# MEC1723N_B0_LJ register map
Vendor: Microchip Technology; Series: MEC172x; File version: 0
CPU: CM4 r1p0, little endian, MPU, FPU, 3 interrupt priority bits, 172 interrupts
Registers are 32-bit, read-write, reset 0x0 unless marked. A register's access mark holds for its fields unless they carry their own. Offsets are from the block's base; [hi:lo] are bit positions; {n}, {i} and the like mark numbered series.

## PCR — The Power, Clocks, and Resets (PCR) Section identifies clock sources, and reset inputs to the chip.
Base 0x40080100
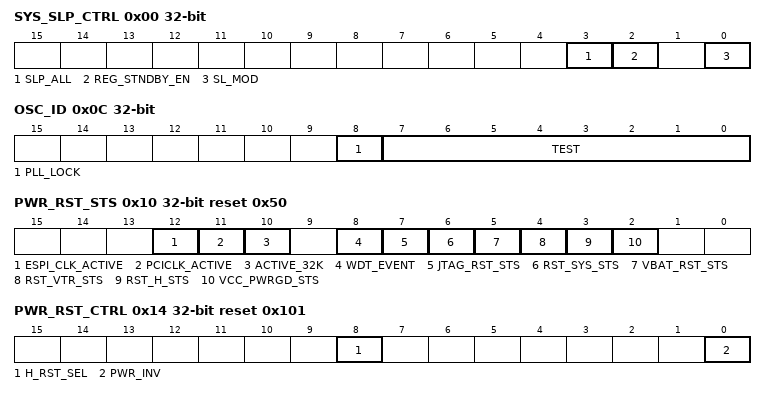
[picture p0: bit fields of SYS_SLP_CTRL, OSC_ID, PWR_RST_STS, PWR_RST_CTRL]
0x00 SYS_SLP_CTRL — System Sleep Control
  [3] SLP_ALL — Initiates the System Sleep mode
  [2] REG_STNDBY_EN — Regulator Standby Enable
  [0] SL_MOD — Selects the System Sleep mode
0x04 PROC_CLK_CTRL reset 0x4 — Processor Clock Control Register [7:0] Processor Clock Divide Value (PROC_DIV)
  [7:0] DIV — Selects the EC clock rate
    1=DIVIDE_BY_1 (1: divide 48 MHz Ring Oscillator by 1); 3=DIVIDE_BY_3 (3: divide 48 MHz Ring Oscillator by 3); 4=DIVIDE_BY_4 (4: divide 48 MHz Ring Oscillator by 4); 16=DIVIDE_BY_16 (16: divide 48 MHz Ring Oscillator by 16); 48=DIVIDE_BY_48 (48: divide 48 MHz Ring Oscillator by 48)
0x08 SLOW_CLK_CTRL reset 0x1E0 — Configures the EC_CLK clock domain
  [9:0] DIV — SLOW_CLOCK_DIVIDE. n=Divide by n; 0=Clock off
0x0C OSC_ID — Oscillator ID Register
  [8] PLL_LOCK — PLL Lock Status
  [7:0] TEST — Test bits
0x10 PWR_RST_STS reset 0x50 — PCR Power Reset Status Register
  [12] ESPI_CLK_ACTIVE
  [11] PCICLK_ACTIVE — PCICLK_ACTIVE (PCICLK_ACTIVE)
  [10] ACTIVE_32K — 32K ACTIVE (ACTIVE_32K)
  [8] WDT_EVENT — Indicates that a WDT_EVENT happened. (R/W1C) 0 = Not active. 1 = A WDT_EVENT occured.
  [7] JTAG_RST_STS — Indicates status of JTAG_TRST# pin. 0 = No JTAG reset occurred since the last time this bit was cleared. 1 = A reset occurred because of a JTAG command.
  [6] RST_SYS_STS — Indicates the status of RESET_SYS.(R/W1C) 0 = No reset occurred since the last time this bit was cleared. 1 = A reset occurred.
  [5] VBAT_RST_STS — VBAT reset status 0 = No reset occurred while VTR was off or since the last time this bit was cleared. 1 = A reset occurred.(R/WC)
  [4] RST_VTR_STS — Indicates the status of RESET_VTR. 0 = reset active. 1 = reset not active.(R/W1C)
  [3] RST_H_STS — Indicates the status of RESET_VCC. 0 = reset active. 1 = reset not active.
  [2] VCC_PWRGD_STS — Indicates the status of VCC_PWRGD. 0 = PWRGD not asserted. 1 = PWRGD asserte.
0x14 PWR_RST_CTRL reset 0x101 — Power Reset Control Register
  [8] H_RST_SEL — Determines what generates the internal platform reset signal. 1=LRESET# pin; 0=eSPI PLTRST# VWire
  [0] PWR_INV — Used by FW to control internal RESET_VCC signal function and external PWROK pin. This bit is read-only when VCC_PWRGD is de-asserted low.
0x18 SYS_RST — System Reset Register
  [8] SOFT_SYS_RST — A write of a 1 forces an assertion of the RESET_SYS reset signal, resetting the device. A write of 0 has no effect.
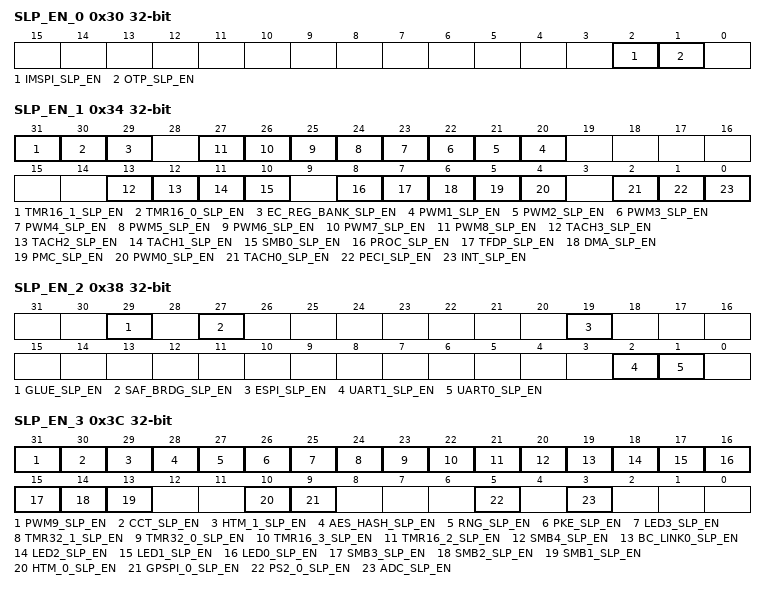
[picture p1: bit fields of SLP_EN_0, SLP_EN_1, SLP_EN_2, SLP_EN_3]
0x30 SLP_EN_0 — Sleep Enable 0 Register
  [2] IMSPI_SLP_EN — IMSPI Sleep Enable
  [1] OTP_SLP_EN — OTP Enable
0x34 SLP_EN_1 — Sleep Enable 1 Register
  [31] TMR16_1_SLP_EN — TIMER16_1 Sleep Enable (TIMER16_1_SLP_EN)
  [30] TMR16_0_SLP_EN — TIMER16_0 Sleep Enable (TIMER16_0_SLP_EN)
  [29] EC_REG_BANK_SLP_EN — EC_REG_BANK Sleep Enable (EC_REG_BANK_SLP_EN)
  [n+19] PWM{n}_SLP_EN (n=1..8) — PWM{n} Sleep Enable (PWM{n}_SLP_EN)
  [13] TACH3_SLP_EN — TACH3 Sleep Enable (TACH3_SLP_EN)
  [12] TACH2_SLP_EN — TACH2 Sleep Enable (TACH2_SLP_EN)
  [11] TACH1_SLP_EN — TACH1 Sleep Enable (TACH1_SLP_EN)
  [10] SMB0_SLP_EN — SMB0 Sleep Enable (SMB0_SLP_EN)
  [8] PROC_SLP_EN — PROCESSOR Sleep Enable (PROCESSOR_SLP_EN)
  [7] TFDP_SLP_EN — TFDP Sleep Enable (TFDP_SLP_EN)
  [6] DMA_SLP_EN — DMA Sleep Enable (DMA_SLP_EN)
  [5] PMC_SLP_EN — PMC Sleep Enable (PMC_SLP_EN)
  [4] PWM0_SLP_EN — PWM0 Sleep Enable (PWM0_SLP_EN)
  [2] TACH0_SLP_EN — TACH0 Sleep Enable (TACH0_SLP_EN)
  [1] PECI_SLP_EN — PECI Sleep Enable
  [0] INT_SLP_EN — Interrupt Sleep Enable
0x38 SLP_EN_2 — Sleep Enable 2 Register
  [29] GLUE_SLP_EN — GLUE Sleep Enable
  [27] SAF_BRDG_SLP_EN — SAF BRIDGE Sleep Enable
  [19] ESPI_SLP_EN — eSPI Sleep Enable
  [2] UART1_SLP_EN — UART 1 Sleep Enable
  [1] UART0_SLP_EN — UART 0 Sleep Enable
0x3C SLP_EN_3 — Sleep Enable 3 Register
  [31] PWM9_SLP_EN — PWM9 Sleep Enable (PWM9_SLP_EN)
  [30] CCT_SLP_EN — Capture Compare Timer Sleep Enable (CCTIMER_SLP_EN)
  [29] HTM_1_SLP_EN — Hibernation TIMER 1 Sleep Enable (HTM_1_SLP_EN)
  [28] AES_HASH_SLP_EN — AES_HASH Sleep Enable
  [27] RNG_SLP_EN — RNG Sleep Enable
  [26] PKE_SLP_EN — PKE Sleep Enable
  [25] LED3_SLP_EN — LED3 Sleep Enable (LED3_SLP_EN)
  [24] TMR32_1_SLP_EN — TIMER32_1 Sleep Enable (TIMER32_1_SLP_EN)
  [23] TMR32_0_SLP_EN — TIMER32_0 Sleep Enable (TIMER32_0_SLP_EN)
  [22] TMR16_3_SLP_EN — TIMER16_3 Sleep Enable (TIMER16_3_SLP_EN)
  [21] TMR16_2_SLP_EN — TIMER16_2 Sleep Enable (TIMER16_2_SLP_EN)
  [20] SMB4_SLP_EN — SMB4 Sleep Enable (SMB4_SLP_EN)
  [19] BC_LINK0_SLP_EN — BC_LINK0 Sleep Enable (BC_LINK0_SLP_EN)
  [18] LED2_SLP_EN — LED2 Sleep Enable (LED2_SLP_EN)
  [17] LED1_SLP_EN — LED1 Sleep Enable (LED1_SLP_EN)
  [16] LED0_SLP_EN — LED0 Sleep Enable (LED0_SLP_EN)
  [15] SMB3_SLP_EN — SMB3 Sleep Enable (SMB3_SLP_EN)
  [14] SMB2_SLP_EN — SMB2 Sleep Enable (SMB2_SLP_EN)
  [13] SMB1_SLP_EN — SMB1 Sleep Enable (SMB1_SLP_EN)
  [10] HTM_0_SLP_EN — Hibernation Timer 0 Sleep Enable (HTM_0_SLP_EN)
  [9] GPSPI_0_SLP_EN — GPSPI 0 Sleep Enable (GPSPI_0_SLP_EN)
  [5] PS2_0_SLP_EN — PS2_0 Sleep Enable (PS2_0_SLP_EN)
  [3] ADC_SLP_EN — ADC Sleep Enable (ADC_SLP_EN)
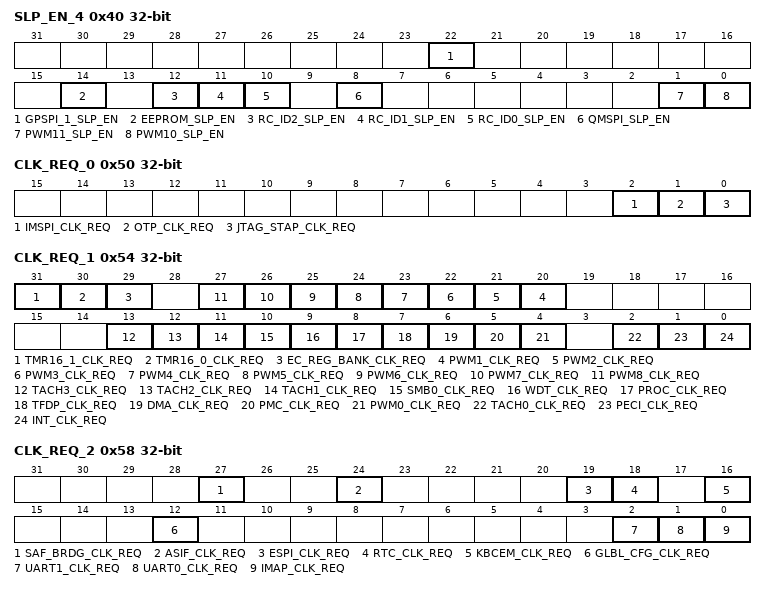
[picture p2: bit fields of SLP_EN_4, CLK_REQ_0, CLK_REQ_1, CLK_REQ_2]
0x40 SLP_EN_4 — Sleep Enable 4 Register
  [22] GPSPI_1_SLP_EN — GPSPI 1 Sleep Enable (GPSPI_1_SLP_EN)
  [14] EEPROM_SLP_EN — EEPROM Sleep Enable (EEPROM_SLP_EN)
  [12] RC_ID2_SLP_EN — RC_ID2 Sleep Enable (RC_ID2_SLP_EN)
  [11] RC_ID1_SLP_EN — RC_ID1 Sleep Enable (RC_ID1_SLP_EN)
  [10] RC_ID0_SLP_EN — RC_ID0 Sleep Enable (RC_ID0_SLP_EN)
  [8] QMSPI_SLP_EN — Quad Master SPI Sleep Enable
  [1] PWM11_SLP_EN — PWM11 Sleep Enable (PWM11_SLP_EN)
  [0] PWM10_SLP_EN — PWM10 Sleep Enable (PWM10_SLP_EN)
0x50 CLK_REQ_0 — Clock Required 0 Register
  [2] IMSPI_CLK_REQ — IMSPI Sleep clock Required
  [1] OTP_CLK_REQ — OTP Enable
  [0] JTAG_STAP_CLK_REQ — JTAG STAP Enable
0x54 CLK_REQ_1 — Clock Required 1 Register
  [31] TMR16_1_CLK_REQ — TIMER16_1 Clock Required (TIMER16_1_CLK_REQ)
  [30] TMR16_0_CLK_REQ — TIMER16_0 Clock Required (TIMER16_0_CLK_REQ)
  [29] EC_REG_BANK_CLK_REQ — EC_REG_BANK Clock Required (EC_REG_BANK_CLK_REQ)
  [n+19] PWM{n}_CLK_REQ (n=1..8) — PWM{n} Clock Required (PWM{n}_CLK_REQ)
  [13] TACH3_CLK_REQ — TACH3 Clock Required (TACH3_CLK_REQ)
  [12] TACH2_CLK_REQ — TACH2 Clock Required (TACH2_CLK_REQ)
  [11] TACH1_CLK_REQ — TACH1 Clock Required (TACH1_CLK_REQ)
  [10] SMB0_CLK_REQ — SMB0 Clock Required (SMB0_CLK_REQ)
  [9] WDT_CLK_REQ — WDT Clock Required (WDT_CLK_REQ)
  [8] PROC_CLK_REQ — PROCESSOR Clock Required (PROCESSOR_CLK_REQ)
  [7] TFDP_CLK_REQ — TFDP Clock Required (TFDP_CLK_REQ)
  [6] DMA_CLK_REQ — DMA Clock Required (DMA_CLK_REQ)
  [5] PMC_CLK_REQ — PMC Clock Required (PMC_CLK_REQ)
  [4] PWM0_CLK_REQ — PWM0 Clock Required (PWM0_CLK_REQ)
  [2] TACH0_CLK_REQ — TACH0 Clock Required (TACH0_CLK_REQ)
  [1] PECI_CLK_REQ — PECI Clock Required
  [0] INT_CLK_REQ — Interrupt Clock Required
0x58 CLK_REQ_2 — Clock Required 2 Register
  [27] SAF_BRDG_CLK_REQ — SAF BRIDGE Clock Required
  [24] ASIF_CLK_REQ — ASIF Clock Required
  [19] ESPI_CLK_REQ — eSPI Clock Required
  [18] RTC_CLK_REQ — RTC Clock Required (RTC_CLK_REQ)
  [16] KBCEM_CLK_REQ — 8042EM Clock Required (8042EM_CLK_REQ)
  [12] GLBL_CFG_CLK_REQ — GLBL_CFG (GLBL_CFG_CLK_REQ)
  [2] UART1_CLK_REQ — UART 1 Clock Required
  [1] UART0_CLK_REQ — UART 0 Clock Required
  [0] IMAP_CLK_REQ — IMAP Clock Required (IMAP_CLK_REQ)
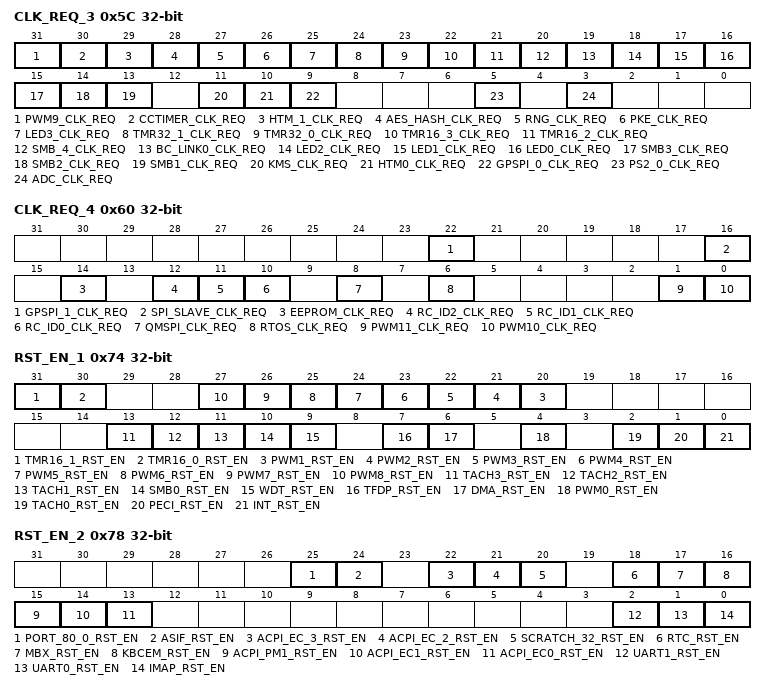
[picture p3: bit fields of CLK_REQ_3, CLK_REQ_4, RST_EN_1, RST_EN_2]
0x5C CLK_REQ_3 — Clock Required 3 Register
  [31] PWM9_CLK_REQ — PWM9 Clock Required (PWM9_CLK_REQ)
  [30] CCTIMER_CLK_REQ — Capture Compare Timer Clock Required (CCTIMER_CLK_REQ)
  [29] HTM_1_CLK_REQ — Hibernation TIMER 1 Clock Required (HTM_1_CLK_REQ)
  [28] AES_HASH_CLK_REQ — AES_HASH Clock Required
  [27] RNG_CLK_REQ — RNG Clock Required
  [26] PKE_CLK_REQ — PKE Clock Required
  [25] LED3_CLK_REQ — LED3 Clock Required (LED3_CLK_REQ)
  [24] TMR32_1_CLK_REQ — TIMER32_1 Clock Required (TIMER32_1_CLK_REQ)
  [23] TMR32_0_CLK_REQ — TIMER32_0 Clock Required (TIMER32_0_CLK_REQ)
  [22] TMR16_3_CLK_REQ — TIMER16_3 Clock Required (TIMER16_3_CLK_REQ)
  [21] TMR16_2_CLK_REQ — TIMER16_2 Clock Required (TIMER16_2_CLK_REQ)
  [20] SMB_4_CLK_REQ — SMB 4 Clock Required (SMB_4_CLK_REQ)
  [19] BC_LINK0_CLK_REQ — BC_LINK0 Clock Required (BC_LINK0_CLK_REQ)
  [18] LED2_CLK_REQ — LED2 Clock Required (LED2_CLK_REQ)
  [17] LED1_CLK_REQ — LED1 Clock Required (LED1_CLK_REQ)
  [16] LED0_CLK_REQ — LED0 Clock Required (LED0_CLK_REQ)
  [15] SMB3_CLK_REQ — SMB3 Clock Required (SMB3_CLK_REQ)
  [14] SMB2_CLK_REQ — SMB2 Clock Required (SMB2_CLK_REQ)
  [13] SMB1_CLK_REQ — SMB1 Clock Required (SMB1_CLK_REQ)
  [11] KMS_CLK_REQ — KEYSCAN Clock Required (KMS_CLK_REQ)
  [10] HTM0_CLK_REQ — Hibernation TIMER 0 Clock Required (HTM_0_CLK_REQ)
  [9] GPSPI_0_CLK_REQ — GPSPI 0 Clock Required (GPSPI_0_CLK_REQ)
  [5] PS2_0_CLK_REQ — PS2_0 Clock Required (PS2_0_CLK_REQ)
  [3] ADC_CLK_REQ — ADC Clock Required (ADC_CLK_REQ)
0x60 CLK_REQ_4 — Clock Required 4 Register
  [22] GPSPI_1_CLK_REQ — GPSPI 1 Clock Required (GPSPI_1_CLK_REQ)
  [16] SPI_SLAVE_CLK_REQ — SPI SLAVE Clock Required (SPI_SLAVE_CLK_REQ)
  [14] EEPROM_CLK_REQ — EEPROM Clock Required (EEPROM_CLK_REQ)
  [12] RC_ID2_CLK_REQ — RC_ID2 Clock Required (RC_ID2_CLK_REQ)
  [11] RC_ID1_CLK_REQ — RC_ID1 Clock Required (RC_ID1_CLK_REQ)
  [10] RC_ID0_CLK_REQ — RC_ID0 Clock Required (RC_ID0_CLK_REQ)
  [8] QMSPI_CLK_REQ — Quad Master SPI Clock Required
  [6] RTOS_CLK_REQ — RTOS Clock Required (RTOS_CLK_REQ)
  [1] PWM11_CLK_REQ — PWM11 Clock Required (PWM11_CLK_REQ)
  [0] PWM10_CLK_REQ — PWM10 Clock Required (PWM10_CLK_REQ)
0x70 RST_EN_0 — Reset Enable 0 Register
  [1] OTP_RST_EN — OTP Reset Enable
0x74 RST_EN_1 — Reset Enable 1 Register
  [31] TMR16_1_RST_EN — TIMER16_1 Reset Enable (TIMER16_1_RST_EN)
  [30] TMR16_0_RST_EN — TIMER16_0 Reset Enable (TIMER16_0_RST_EN)
  [n+19] PWM{n}_RST_EN (n=1..8) — PWM{n} Reset Enable (PWM{n}_RST_EN)
  [13] TACH3_RST_EN — TACH3 Reset Enable (TACH3_RST_EN)
  [12] TACH2_RST_EN — TACH2 Reset Enable (TACH2_RST_EN)
  [11] TACH1_RST_EN — TACH1 Reset Enable (TACH1_RST_EN)
  [10] SMB0_RST_EN — SMB0 Reset Enable (SMB0_RST_EN)
  [9] WDT_RST_EN — WDT Reset Enable (WDT_RST_EN)
  [7] TFDP_RST_EN — TFDP Reset Enable (TFDP_RST_EN)
  [6] DMA_RST_EN — DMA Reset Enable (DMA_RST_EN)
  [4] PWM0_RST_EN — PWM0 Reset Enable (PWM0_RST_EN)
  [2] TACH0_RST_EN — TACH0 Reset Enable (TACH0_RST_EN)
  [1] PECI_RST_EN — PECI Reset Enable
  [0] INT_RST_EN — Interrupt Reset Enable
0x78 RST_EN_2 — Reset Enable 2 Register
  [25] PORT_80_0_RST_EN — Port 80 0 Reset Enable
  [24] ASIF_RST_EN — ASIF Reset Enable
  [22] ACPI_EC_3_RST_EN — ACPI EC 3 Reset Enable (ACPI_EC_3_RST_EN)
  [21] ACPI_EC_2_RST_EN — ACPI EC 2 Reset Enable (ACPI_EC_2_RST_EN)
  [20] SCRATCH_32_RST_EN — SCRATCH 32 Reset Enable
  [18] RTC_RST_EN — RTC Reset Enable (RTC_RST_EN)
  [17] MBX_RST_EN — Mailbox Reset Enable (MBX_RST_EN)
  [16] KBCEM_RST_EN — 8042EM Reset Enable (8042EM_RST_EN)
  [15] ACPI_PM1_RST_EN — ACPI PM1 Reset Enable (ACPI_PM1_RST_EN)
  [14] ACPI_EC1_RST_EN — ACPI EC 1 Reset Enable (ACPI_EC_1_RST_EN)
  [13] ACPI_EC0_RST_EN — ACPI EC 0 Reset Enable (ACPI_EC_0_RST_EN)
  [2] UART1_RST_EN — UART 1 Reset Enable
  [1] UART0_RST_EN — UART 0 Reset Enable
  [0] IMAP_RST_EN — IMAP Reset Enable (IMAP_RST_EN)
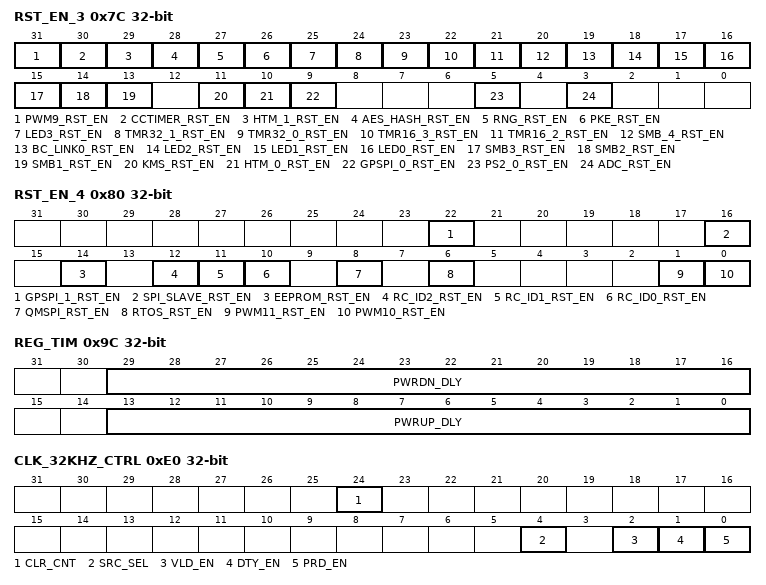
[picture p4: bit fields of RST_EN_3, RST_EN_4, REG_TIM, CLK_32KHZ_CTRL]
0x7C RST_EN_3 — Reset Enable 3 Register
  [31] PWM9_RST_EN — PWM9 Reset Enable (PWM9_RST_EN)
  [30] CCTIMER_RST_EN — Capture Compare Timer Reset Enable (CCTIMER_RST_EN)
  [29] HTM_1_RST_EN — Hibernation TIMER 1 Reset Enable (HTM_1_RST_EN)
  [28] AES_HASH_RST_EN — AES_HASH Reset Enable
  [27] RNG_RST_EN — RNG Reset Enable
  [26] PKE_RST_EN — PKE Reset Enable
  [25] LED3_RST_EN — LED3 Reset Enable (LED3_RST_EN)
  [24] TMR32_1_RST_EN — TIMER32_1 Reset Enable (TIMER32_1_RST_EN)
  [23] TMR32_0_RST_EN — TIMER32_0 Reset Enable (TIMER32_0_RST_EN)
  [22] TMR16_3_RST_EN — TIMER16_3 Reset Enable (TIMER16_3_RST_EN)
  [21] TMR16_2_RST_EN — TIMER16_2 Reset Enable (TIMER16_2_RST_EN)
  [20] SMB_4_RST_EN — SMB 4 Reset Enable (SMB_4_RST_EN)
  [19] BC_LINK0_RST_EN — BC_LINK0 Reset Enable (BC_LINK0_RST_EN)
  [18] LED2_RST_EN — LED2 Reset Enable (LED2_RST_EN)
  [17] LED1_RST_EN — LED1 Reset Enable (LED1_RST_EN)
  [16] LED0_RST_EN — LED0 Reset Enable (LED0_RST_EN)
  [15] SMB3_RST_EN — SMB3 Reset Enable (SMB3_RST_EN)
  [14] SMB2_RST_EN — SMB2 Reset Enable (SMB2_RST_EN)
  [13] SMB1_RST_EN — SMB1 Reset Enable (SMB1_RST_EN)
  [11] KMS_RST_EN — KEYSCAN Reset Enable (KMS_RST_EN)
  [10] HTM_0_RST_EN — Hibernation TIMER 0 Reset Enable (HTM_0_RST_EN)
  [9] GPSPI_0_RST_EN — GPSPI 0 Reset Enable (GPSPI_0_RST_EN)
  [5] PS2_0_RST_EN — PS2_0 Reset Enable (PS2_0_RST_EN)
  [3] ADC_RST_EN — ADC Reset Enable (ADC_RST_EN)
0x80 RST_EN_4 — Reset Enable 4 Register
  [22] GPSPI_1_RST_EN — GPSPI 1 Reset Enable (GPSPI_1_RST_EN)
  [16] SPI_SLAVE_RST_EN — SPI SLAVE Reset Enable (SPI_SLAVE_RST_EN)
  [14] EEPROM_RST_EN — EEPROM Reset Enable (EEPROM_RST_EN)
  [12] RC_ID2_RST_EN — RC_ID2 Reset Enable (RC_ID2_RST_EN)
  [11] RC_ID1_RST_EN — RC_ID1 Reset Enable (RC_ID1_RST_EN)
  [10] RC_ID0_RST_EN — RC_ID0 Reset Enable (RC_ID0_RST_EN)
  [8] QMSPI_RST_EN — Quad Master SPI Reset Enable
  [6] RTOS_RST_EN — RTOS Reset Enable (RTOS_RST_EN)
  [1] PWM11_RST_EN — PWM11 Reset Enable (PWM11_RST_EN)
  [0] PWM10_RST_EN — PWM10 Reset Enable (PWM10_RST_EN)
0x84 LOCK_REG reset 0xA6382D4D — LOCK Register
  [31:0] PCR_RST_EN_LOCK — PCR Reset Enable Lock Register.
0x88 SFT_VBAT_POR — SOFT VBAT Register
  [0] SFT_VBAT_POR — SOFT VBAT POWER ON RESET.
0x8C PLL_REF reset 0x3 — PLL reference clock select.
  [1:0] PLL_REF — Source 32kHz MUX Select for the PLL reference clock source. 0 = Internal Silicon Oscillator 1 = XTAL 2 = VTR PIN 32KHZ_IN 3 = NONE-OFF
0x94 REG_CTRL_RUN ro — Regulator Control Running Register
  [31:0] CTRL_RUN — Regulator Control Running Register.
0x98 REG_CTRL_SLP ro — Regulator Control Sleeping Register
  [31:0] CTRL_SLP — Regulator Control Running Register.
0x9C REG_TIM ro — Regulator Time Register
  [29:16] PWRDN_DLY — Regulator Power Down delay Register.
  [13:0] PWRUP_DLY — Regulator Power Up delay Register.
0xA4 BNDGP_CTRL_RUN ro — Bandgap Control Running Register
  [31:0] CTRL_RUN — Regulator Control Running Register.
0xA8 BNDGP_CTRL_SLP ro — Bandgap Control Sleeping Register
  [31:0] CTRL_SLP — Regulator Control Running Register.
0xC0 CLK_PRD ro — 32KHz Period Counter Register
  [31:0] CLK_PRD — Counter 32khz period Counts system clock cycles between 2 positive edges of an 32kHz clock.
0xC4 CLK_HGHPLS ro — 32KHz Clock High Pulse Register
  [31:0] CLK_HGHPLS — Counter 32khz High Counts how many system clock cycles the 32kHz clock remains HIGH for.
0xC8 CLK_MINPRD ro — 32KHz Clock Min Period Register
  [31:0] CLK_MINPRD — This is the minimum period count that is acceptable for the 32kHz counter to flag a PASS status.
0xCC CLK_MAXPRD — 32KHz Clock Max Period Register
  [31:0] CLK_MAXPRD — This is the maximum period count that is acceptable for the 32kHz counter to flag a PASS status.
0xD0 CLK_DTYVRTN ro — 32KHz Clock Duty Variation Register
  [31:0] CLK_DTYVRTN — This is the difference in system clocks between the 32kHz clocks High Pulse Width and its Low Pulse Width.
0xD4 CLK_MAXDTYVRTN — 32KHz Maximum Clock Duty Variation Register
  [31:0] CLK_MAXDTYVRTN — This is the difference maximum variation allowed to generate a PASS condition for the 32kHz clock
0xD8 CLK_VLDCNT ro — 32KHz Clock Valid Count Register
  [31:0] CLK_VLDCNT — This counts the number of valid 32kHz periods and pulse width variations measured in a row. This count increments on a PASS and will reset on a FAIL.
0xDC CLK_VLDMIN — 32KHz Clock Valid Minimum Count Register
  [31:0] CLK_VLDMIN — This is the minimum value of Counter 32kHz Valid Count that will flag the status Counter Valid.
0xE0 CLK_32KHZ_CTRL — 32KHz Clock Control Register
  [24] CLR_CNT — Counter 32kHz Clear Clears the counters.
  [4] SRC_SEL — Counter 32kHz Source Selects the source 32kHz clock that is measured.
  [2] VLD_EN — Enables the Counter for Valid count.
  [1] DTY_EN — Enables the Duty cycle Counter.
  [0] PRD_EN — Enables the Period Counter.
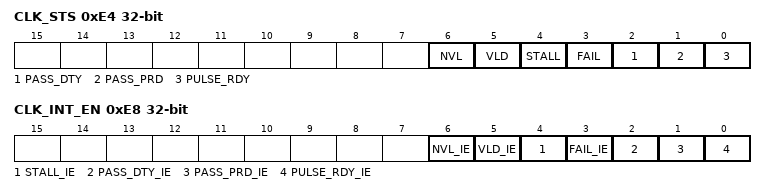
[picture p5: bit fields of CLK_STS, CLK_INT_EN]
0xE4 CLK_STS — 32KHz Clock Monitor Status Register
  [6] NVL — Counter 32kHz Unwell Status.
  [5] VLD — Counter 32kHz Valid Status.
  [4] STALL — Counter 32kHz Stall Status.
  [3] FAIL — Counter 32kHz Fail Status.
  [2] PASS_DTY — Counter 32kHz Pass Duty Status.
  [1] PASS_PRD — Counter 32kHz Pass Period Status.
  [0] PULSE_RDY — Counter 32kHz Pulse Ready Status.
0xE8 CLK_INT_EN — 32KHz Clock Monitor Interrupt Enable Register
  [6] NVL_IE — Counter 32kHz Unwell Interrupt Enable.
  [5] VLD_IE — Counter 32kHz Valid Interrupt Enable.
  [4] STALL_IE — Counter 32kHz Stall Interrupt Enable.
  [3] FAIL_IE — Counter 32kHz Fail Interrupt Enable.
  [2] PASS_DTY_IE — Counter 32kHz Pass Duty Interrupt Enable.
  [1] PASS_PRD_IE — Counter 32kHz Pass Period Interrupt Enable.
  [0] PULSE_RDY_IE — Counter 32kHz Pulse Ready Interrupt Enable.
